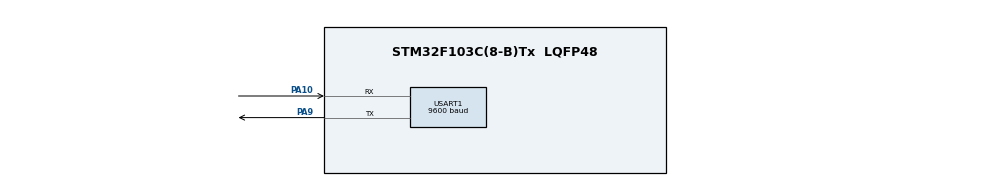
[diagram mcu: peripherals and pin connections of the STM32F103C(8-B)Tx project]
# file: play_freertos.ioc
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FREERTOS.Tasks01=defaultTask,0,128,StartDefaultTask,Default,NULL,Dynamic,NULL,NULL
FREERTOS.configGENERATE_RUN_TIME_STATS=1
FREERTOS.configTICK_RATE_HZ=1
FREERTOS.configTOTAL_HEAP_SIZE=6144
FREERTOS.configUSE_TRACE_FACILITY=1
Mcu.Family=STM32F1
Mcu.Name=STM32F103C(8-B)Tx
Mcu.Package=LQFP48
NVIC.PriorityGroup=NVIC_PRIORITYGROUP_4
NVIC.TIM1_UP_IRQn=true\:0\:0\:false\:false\:true\:false\:false\:true
NVIC.TIM3_IRQn=true\:5\:0\:true\:false\:true\:true\:true\:true
NVIC.TimeBase=TIM1_UP_IRQn
NVIC.TimeBaseIP=TIM1
PA10.Mode=Asynchronous
PA10.Signal=USART1_RX
PA13.Mode=Serial_Wire
PA13.Signal=SYS_JTMS-SWDIO
PA14.Mode=Serial_Wire
PA14.Signal=SYS_JTCK-SWCLK
PA9.Mode=Asynchronous
PA9.Signal=USART1_TX
PD0-OSC_IN.Mode=HSE-External-Clock-Source
PD0-OSC_IN.Signal=RCC_OSC_IN
PD1-OSC_OUT.Mode=HSE-External-Clock-Source
PD1-OSC_OUT.Signal=RCC_OSC_OUT
ProjectManager.HeapSize=0x200
ProjectManager.StackSize=0x400
ProjectManager.TargetToolchain=STM32CubeIDE
RCC.APB1Freq_Value=8000000
RCC.APB2Freq_Value=8000000
TIM2.Period=100
TIM2.Prescaler=80
TIM3.Period=500
TIM3.Prescaler=8000
USART1.BaudRate=9600
USART1.VirtualMode=VM_ASYNC
VP_FREERTOS_VS_CMSIS_V1.Mode=CMSIS_V1
VP_SYS_VS_tim1.Mode=TIM1
VP_TIM2_VS_ClockSourceINT.Mode=Internal
VP_TIM3_VS_ClockSourceINT.Mode=Internal
board=custom

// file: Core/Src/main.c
/* USER CODE BEGIN Header */
/**
 ******************************************************************************
 * @file           : main.c
 * @brief          : Main program body
 ******************************************************************************
 * @attention
 *
 * <h2><center>&copy; Copyright (c) 2020 STMicroelectronics.
 * All rights reserved.</center></h2>
 *
 * This software component is licensed by ST under BSD 3-Clause license,
 * the "License"; You may not use this file except in compliance with the
 * License. You may obtain a copy of the License at:
 *                        opensource.org/licenses/BSD-3-Clause
 *
 ******************************************************************************
 */
/* USER CODE END Header */
#include "main.h"
#include "cmsis_os.h"

TIM_HandleTypeDef htim2;
TIM_HandleTypeDef htim3;

UART_HandleTypeDef huart1;

osThreadId defaultTaskHandle;
/* USER CODE BEGIN PV */

osThreadId task1Handle;
osThreadId task2Handle;
osThreadId task3Handle;
osThreadId intTaskHandle;

osSemaphoreId intBinarySemHandle;

/* USER CODE END PV */

void SystemClock_Config(void);
static void MX_GPIO_Init(void);
static void MX_TIM2_Init(void);
static void MX_USART1_UART_Init(void);
static void MX_TIM3_Init(void);
void StartDefaultTask(void const *argument);

/* USER CODE BEGIN 0 */

void StartTask1(void const *argument) {
	/* USER CODE BEGIN 5 */
	/* Infinite loop */

	char buff[] = "1";
	for (;;) {
		HAL_UART_AbortTransmit(&huart1);
		HAL_UART_Transmit(&huart1, &buff, strlen(&buff), 100);
	}
	/* USER CODE END 5 */
}

void StartTask2(void const *argument) {
	/* USER CODE BEGIN 5 */
	/* Infinite loop */
	char buff[] = "2";
	for (;;) {
		HAL_UART_AbortTransmit(&huart1);
		HAL_UART_Transmit(&huart1, &buff, strlen(&buff), 100);
	}
	/* USER CODE END 5 */
}

void StartTask3(void const *argument) {
	/* USER CODE BEGIN 5 */
	/* Infinite loop */
	char buff[] = "3";
	for (;;) {
		HAL_UART_AbortTransmit(&huart1);
		HAL_UART_Transmit(&huart1, &buff, strlen(&buff), 100);
	}
	/* USER CODE END 5 */
}

void interrupt_handler(void const *argument) {
	for (;;) {
		osSemaphoreWait(intBinarySemHandle, osWaitForever);
		char buff[] = "interrupt";
		HAL_UART_AbortTransmit(&huart1);
		HAL_UART_Transmit(&huart1, &buff, strlen(&buff), 100);
	}
}

/* USER CODE END 0 */

int main(void) {

	/* MCU Configuration--------------------------------------------------------*/

	/* Reset of all peripherals, Initializes the Flash interface and the Systick. */
	HAL_Init();

	/* Configure the system clock */
	SystemClock_Config();

	/* Initialize all configured peripherals */
	MX_GPIO_Init();
	MX_TIM2_Init();
	MX_USART1_UART_Init();
	MX_TIM3_Init();

	/* USER CODE BEGIN RTOS_SEMAPHORES */
	/* add semaphores, ... */

	osSemaphoreDef(intBinarySem);
	intBinarySemHandle = osSemaphoreCreate(osSemaphore(intBinarySem), 1);
	vQueueAddToRegistry(intBinarySemHandle, "intBinarySem");

	/* USER CODE END RTOS_SEMAPHORES */

	/* Create the thread(s) */
	/* definition and creation of defaultTask */
//	osThreadDef(defaultTask, StartDefaultTask, osPriorityNormal, 0, 128);
//	defaultTaskHandle = osThreadCreate(osThread(defaultTask), NULL);
	/* USER CODE BEGIN RTOS_THREADS */
	/* add threads, ... */

	osThreadDef(task1, StartTask1, osPriorityNormal, 0, 256);
	task1Handle = osThreadCreate(osThread(task1), NULL);

	osThreadDef(task2, StartTask2, osPriorityNormal, 0, 256);
	task2Handle = osThreadCreate(osThread(task2), NULL);

	osThreadDef(task3, StartTask3, osPriorityNormal, 0, 256);
	task3Handle = osThreadCreate(osThread(task3), NULL);

//	/*----- TURN ON TIMER INTERRUPTS ----*/
//	osThreadDef(intTask, interrupt_handler, osPriorityNormal, 0, 256);
//	intTaskHandle = osThreadCreate(osThread(intTask), NULL);
//
//	HAL_TIM_Base_Start_IT(&htim3);
//	/*-----END-----*/

	/* USER CODE END RTOS_THREADS */

	/* Start scheduler */
	osKernelStart();

	/* We should never get here as control is now taken by the scheduler */
	/* Infinite loop */
	while (1) {

	}
}

void SystemClock_Config(void) {
	RCC_OscInitTypeDef RCC_OscInitStruct = { 0 };
	RCC_ClkInitTypeDef RCC_ClkInitStruct = { 0 };

	/** Initializes the RCC Oscillators according to the specified parameters
	 * in the RCC_OscInitTypeDef structure.
	 */
	RCC_OscInitStruct.OscillatorType = RCC_OSCILLATORTYPE_HSI;
	RCC_OscInitStruct.HSIState = RCC_HSI_ON;
	RCC_OscInitStruct.HSICalibrationValue = RCC_HSICALIBRATION_DEFAULT;
	RCC_OscInitStruct.PLL.PLLState = RCC_PLL_NONE;
	if (HAL_RCC_OscConfig(&RCC_OscInitStruct) != HAL_OK) {
		Error_Handler();
	}
	/** Initializes the CPU, AHB and APB buses clocks
	 */
	RCC_ClkInitStruct.ClockType = RCC_CLOCKTYPE_HCLK | RCC_CLOCKTYPE_SYSCLK
			| RCC_CLOCKTYPE_PCLK1 | RCC_CLOCKTYPE_PCLK2;
	RCC_ClkInitStruct.SYSCLKSource = RCC_SYSCLKSOURCE_HSI;
	RCC_ClkInitStruct.AHBCLKDivider = RCC_SYSCLK_DIV1;
	RCC_ClkInitStruct.APB1CLKDivider = RCC_HCLK_DIV1;
	RCC_ClkInitStruct.APB2CLKDivider = RCC_HCLK_DIV1;

	if (HAL_RCC_ClockConfig(&RCC_ClkInitStruct, FLASH_LATENCY_0) != HAL_OK) {
		Error_Handler();
	}
}

static void MX_TIM2_Init(void) {

	TIM_ClockConfigTypeDef sClockSourceConfig = { 0 };
	TIM_MasterConfigTypeDef sMasterConfig = { 0 };

	htim2.Instance = TIM2;
	htim2.Init.Prescaler = 80;
	htim2.Init.CounterMode = TIM_COUNTERMODE_UP;
	htim2.Init.Period = 100;
	htim2.Init.ClockDivision = TIM_CLOCKDIVISION_DIV1;
	htim2.Init.AutoReloadPreload = TIM_AUTORELOAD_PRELOAD_DISABLE;
	if (HAL_TIM_Base_Init(&htim2) != HAL_OK) {
		Error_Handler();
	}
	sClockSourceConfig.ClockSource = TIM_CLOCKSOURCE_INTERNAL;
	if (HAL_TIM_ConfigClockSource(&htim2, &sClockSourceConfig) != HAL_OK) {
		Error_Handler();
	}
	sMasterConfig.MasterOutputTrigger = TIM_TRGO_RESET;
	sMasterConfig.MasterSlaveMode = TIM_MASTERSLAVEMODE_DISABLE;
	if (HAL_TIMEx_MasterConfigSynchronization(&htim2, &sMasterConfig)
			!= HAL_OK) {
		Error_Handler();
	}

}

static void MX_TIM3_Init(void) {

	TIM_ClockConfigTypeDef sClockSourceConfig = { 0 };
	TIM_MasterConfigTypeDef sMasterConfig = { 0 };

	htim3.Instance = TIM3;
	htim3.Init.Prescaler = 8000;
	htim3.Init.CounterMode = TIM_COUNTERMODE_UP;
	htim3.Init.Period = 500;
	htim3.Init.ClockDivision = TIM_CLOCKDIVISION_DIV1;
	htim3.Init.AutoReloadPreload = TIM_AUTORELOAD_PRELOAD_DISABLE;
	if (HAL_TIM_Base_Init(&htim3) != HAL_OK) {
		Error_Handler();
	}
	sClockSourceConfig.ClockSource = TIM_CLOCKSOURCE_INTERNAL;
	if (HAL_TIM_ConfigClockSource(&htim3, &sClockSourceConfig) != HAL_OK) {
		Error_Handler();
	}
	sMasterConfig.MasterOutputTrigger = TIM_TRGO_RESET;
	sMasterConfig.MasterSlaveMode = TIM_MASTERSLAVEMODE_DISABLE;
	if (HAL_TIMEx_MasterConfigSynchronization(&htim3, &sMasterConfig)
			!= HAL_OK) {
		Error_Handler();
	}

}

static void MX_USART1_UART_Init(void) {

	huart1.Instance = USART1;
	huart1.Init.BaudRate = 9600;
	huart1.Init.WordLength = UART_WORDLENGTH_8B;
	huart1.Init.StopBits = UART_STOPBITS_1;
	huart1.Init.Parity = UART_PARITY_NONE;
	huart1.Init.Mode = UART_MODE_TX_RX;
	huart1.Init.HwFlowCtl = UART_HWCONTROL_NONE;
	huart1.Init.OverSampling = UART_OVERSAMPLING_16;
	if (HAL_UART_Init(&huart1) != HAL_OK) {
		Error_Handler();
	}

}

static void MX_GPIO_Init(void) {

	/* GPIO Ports Clock Enable */
	__HAL_RCC_GPIOD_CLK_ENABLE();
	__HAL_RCC_GPIOA_CLK_ENABLE();

}

void HAL_TIM_PeriodElapsedCallback(TIM_HandleTypeDef *htim) {
	if (htim->Instance == TIM1) {
		HAL_IncTick();
	}
	/* USER CODE BEGIN Callback 1 */

	if (htim->Instance == TIM3) {
		osSemaphoreRelease(intBinarySemHandle);
	}

	/* USER CODE END Callback 1 */
}

void Error_Handler(void) {
}

/************************ (C) COPYRIGHT STMicroelectronics *****END OF FILE****/

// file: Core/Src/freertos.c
/* USER CODE BEGIN Header */
/**
 ******************************************************************************
 * File Name          : freertos.c
 * Description        : Code for freertos applications
 ******************************************************************************
 * @attention
 *
 * <h2><center>&copy; Copyright (c) 2020 STMicroelectronics.
 * All rights reserved.</center></h2>
 *
 * This software component is licensed by ST under Ultimate Liberty license
 * SLA0044, the "License"; You may not use this file except in compliance with
 * the License. You may obtain a copy of the License at:
 *                             www.st.com/SLA0044
 *
 ******************************************************************************
 */
/* USER CODE END Header */

#include "FreeRTOS.h"
#include "task.h"
#include "main.h"

/* USER CODE BEGIN Variables */

extern TIM_HandleTypeDef htim2;

/* USER CODE END Variables */

/* GetIdleTaskMemory prototype (linked to static allocation support) */
void vApplicationGetIdleTaskMemory( StaticTask_t **ppxIdleTaskTCBBuffer, StackType_t **ppxIdleTaskStackBuffer, uint32_t *pulIdleTaskStackSize );

/* Hook prototypes */
void configureTimerForRunTimeStats(void);
unsigned long getRunTimeCounterValue(void);

/* USER CODE BEGIN 1 */
/* Functions needed when configGENERATE_RUN_TIME_STATS is on */
__weak void configureTimerForRunTimeStats(void) {
	HAL_TIM_Base_Start(&htim2);
}

__weak unsigned long getRunTimeCounterValue(void) {
	static unsigned long counter = 0;

	counter += __HAL_TIM_GET_COUNTER(&htim2);
	__HAL_TIM_SET_COUNTER(&htim2, 0);

	return counter;

}
/* USER CODE END 1 */

/* USER CODE BEGIN GET_IDLE_TASK_MEMORY */
static StaticTask_t xIdleTaskTCBBuffer;
static StackType_t xIdleStack[configMINIMAL_STACK_SIZE];

void vApplicationGetIdleTaskMemory(StaticTask_t **ppxIdleTaskTCBBuffer,
		StackType_t **ppxIdleTaskStackBuffer, uint32_t *pulIdleTaskStackSize) {
	*ppxIdleTaskTCBBuffer = &xIdleTaskTCBBuffer;
	*ppxIdleTaskStackBuffer = &xIdleStack[0];
	*pulIdleTaskStackSize = configMINIMAL_STACK_SIZE;
	/* place for user code */
}
/* USER CODE END GET_IDLE_TASK_MEMORY */

/************************ (C) COPYRIGHT STMicroelectronics *****END OF FILE****/
